AUTOSAR XML (schema 4.0)
package /Powertrain_Components
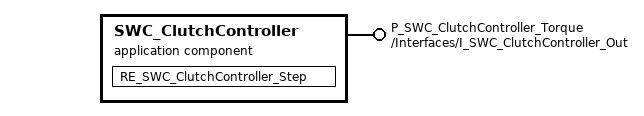
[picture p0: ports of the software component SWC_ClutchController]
  application sw component type SWC_ClutchController  # AUTOSAR Application SWC SWC_ClutchController for Powertrain Control
    provide port P_SWC_ClutchController_Torque: provided-interface=/Interfaces/I_SWC_ClutchController_Out
    behavior SWC_ClutchController_Behavior
      runnable RE_SWC_ClutchController_Step: symbol=SWC_ClutchController_Step
  sender receiver interface I_SWC_ClutchController_Out
    data DE_SWC_ClutchController_TorqueDemand: type=/AUTOSAR/Platform/uint32
